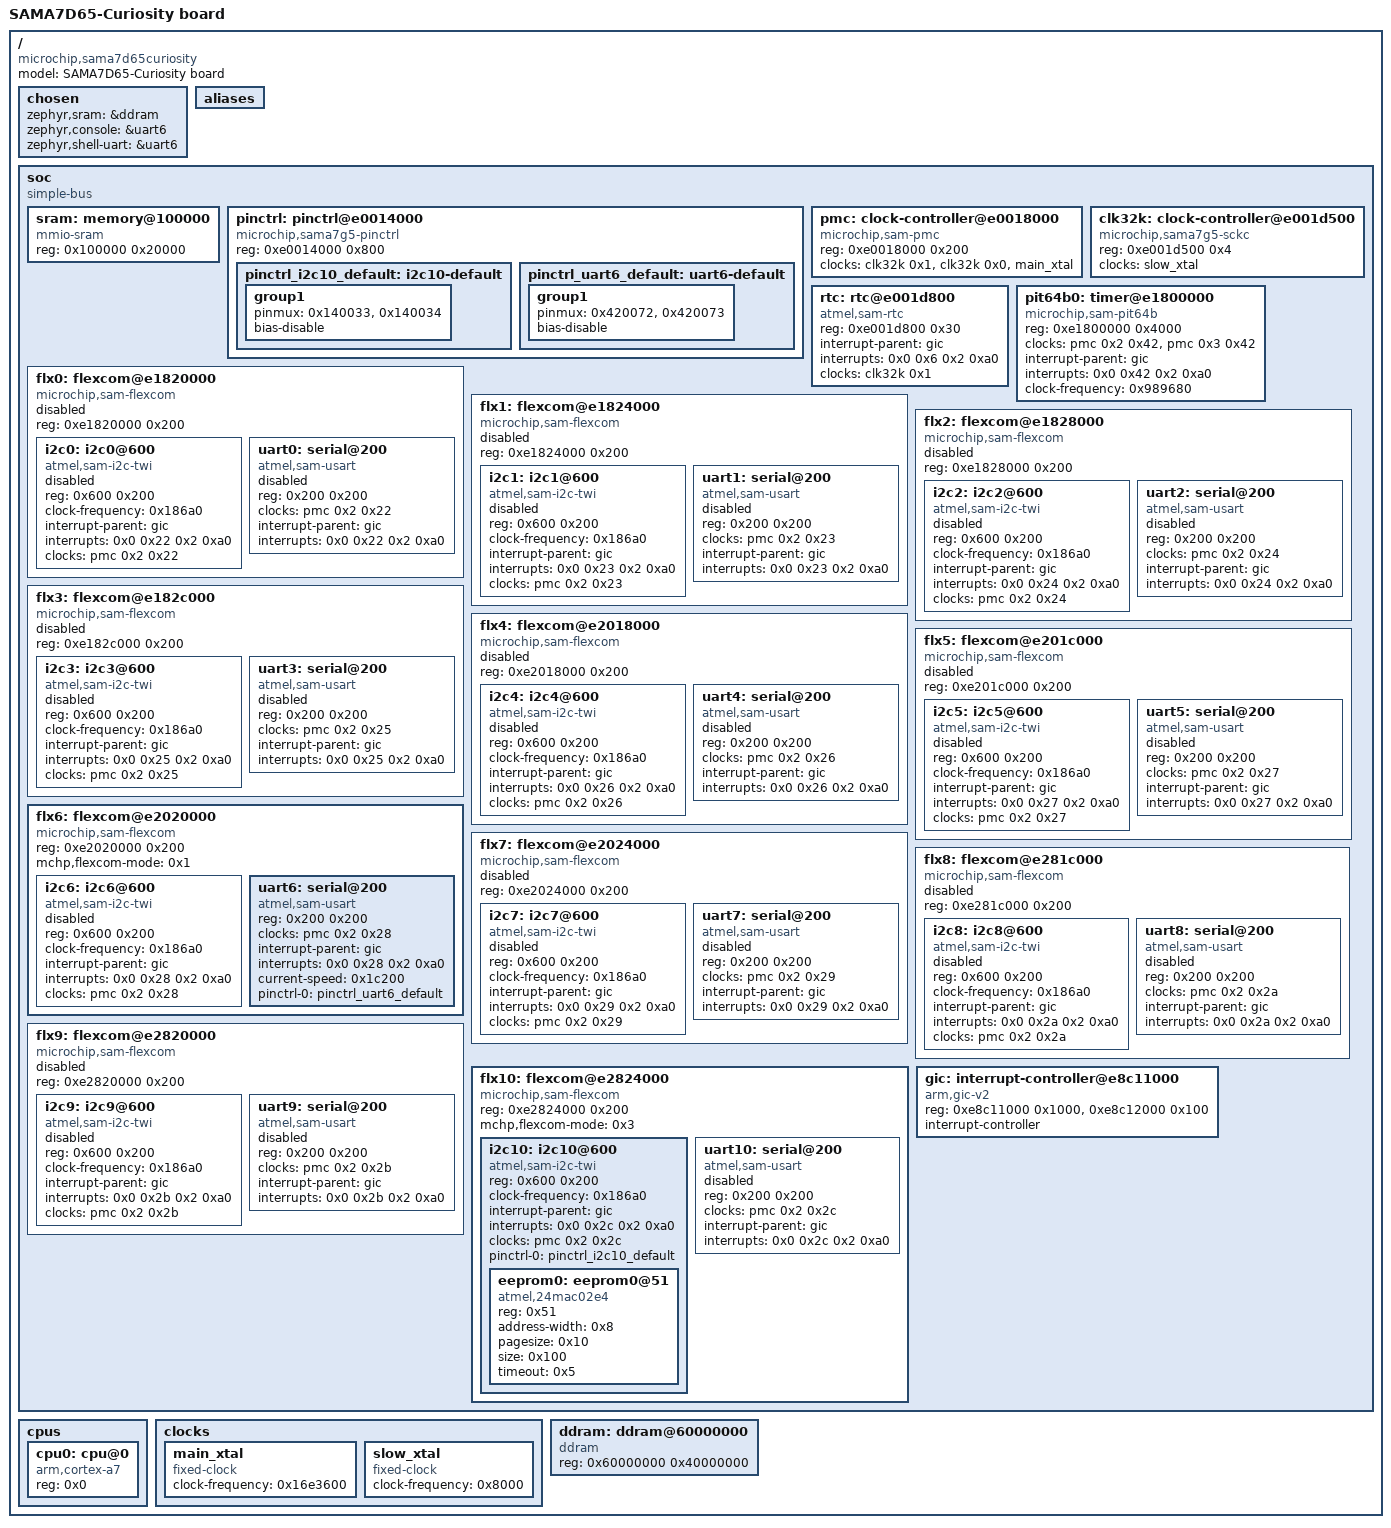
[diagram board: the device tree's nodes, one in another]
/dts-v1/;

/* node '/' defined in zephyr/dts/common/skeleton.dtsi:9 */
/ {
	#address-cells = < 0x1 >;                   /* in zephyr/dts/common/skeleton.dtsi:10 */
	#size-cells = < 0x1 >;                      /* in zephyr/dts/common/skeleton.dtsi:11 */
	model = "SAMA7D65-Curiosity board";         /* in zephyr/boards/microchip/sam/sama7d65_curiosity/sama7d65_curiosity.dts:15 */
	compatible = "microchip,sama7d65curiosity",
	             "microchip,sama7d6",
	             "microchip,sama7";             /* in zephyr/boards/microchip/sam/sama7d65_curiosity/sama7d65_curiosity.dts:16 */

	/* node '/chosen' defined in zephyr/dts/common/skeleton.dtsi:13 */
	chosen {
		zephyr,sram = &ddram;       /* in zephyr/boards/microchip/sam/sama7d65_curiosity/sama7d65_curiosity.dts:19 */
		zephyr,console = &uart6;    /* in zephyr/boards/microchip/sam/sama7d65_curiosity/sama7d65_curiosity.dts:20 */
		zephyr,shell-uart = &uart6; /* in zephyr/boards/microchip/sam/sama7d65_curiosity/sama7d65_curiosity.dts:21 */
	};

	/* node '/aliases' defined in zephyr/dts/common/skeleton.dtsi:15 */
	aliases {
	};

	/* node '/soc' defined in zephyr/dts/arm/armv7-a.dtsi:10 */
	soc {
		#address-cells = < 0x1 >;  /* in zephyr/dts/arm/armv7-a.dtsi:11 */
		#size-cells = < 0x1 >;     /* in zephyr/dts/arm/armv7-a.dtsi:12 */
		compatible = "simple-bus"; /* in zephyr/dts/arm/armv7-a.dtsi:13 */
		ranges;                    /* in zephyr/dts/arm/armv7-a.dtsi:14 */

		/* node '/soc/memory@100000' defined in zephyr/dts/arm/microchip/sam/sama7d6.dtsi:42 */
		sram: memory@100000 {
			compatible = "mmio-sram";   /* in zephyr/dts/arm/microchip/sam/sama7d6.dtsi:43 */
			reg = < 0x100000 0x20000 >; /* in zephyr/dts/arm/microchip/sam/sama7d6.dtsi:44 */
		};

		/* node '/soc/pinctrl@e0014000' defined in zephyr/dts/arm/microchip/sam/sama7d6.dtsi:47 */
		pinctrl: pinctrl@e0014000 {
			compatible = "microchip,sama7g5-pinctrl"; /* in zephyr/dts/arm/microchip/sam/sama7d6.dtsi:48 */
			reg = < 0xe0014000 0x800 >;               /* in zephyr/dts/arm/microchip/sam/sama7d6.dtsi:49 */

			/* node '/soc/pinctrl@e0014000/i2c10-default' defined in zephyr/boards/microchip/sam/sama7d65_curiosity/sama7d65_curiosity.dts:74 */
			pinctrl_i2c10_default: i2c10-default {
				phandle = < 0x7 >; /* in zephyr/boards/microchip/sam/sama7d65_curiosity/sama7d65_curiosity.dts:57 */

				/* node '/soc/pinctrl@e0014000/i2c10-default/group1' defined in zephyr/boards/microchip/sam/sama7d65_curiosity/sama7d65_curiosity.dts:75 */
				group1 {
					pinmux = < 0x140033 >,
					         < 0x140034 >; /* in zephyr/boards/microchip/sam/sama7d65_curiosity/sama7d65_curiosity.dts:76 */
					bias-disable;          /* in zephyr/boards/microchip/sam/sama7d65_curiosity/sama7d65_curiosity.dts:78 */
				};
			};

			/* node '/soc/pinctrl@e0014000/uart6-default' defined in zephyr/boards/microchip/sam/sama7d65_curiosity/sama7d65_curiosity.dts:82 */
			pinctrl_uart6_default: uart6-default {
				phandle = < 0x6 >; /* in zephyr/boards/microchip/sam/sama7d65_curiosity/sama7d65_curiosity.dts:46 */

				/* node '/soc/pinctrl@e0014000/uart6-default/group1' defined in zephyr/boards/microchip/sam/sama7d65_curiosity/sama7d65_curiosity.dts:83 */
				group1 {
					pinmux = < 0x420072 >,
					         < 0x420073 >; /* in zephyr/boards/microchip/sam/sama7d65_curiosity/sama7d65_curiosity.dts:84 */
					bias-disable;          /* in zephyr/boards/microchip/sam/sama7d65_curiosity/sama7d65_curiosity.dts:86 */
				};
			};
		};

		/* node '/soc/clock-controller@e0018000' defined in zephyr/dts/arm/microchip/sam/sama7d6.dtsi:52 */
		pmc: clock-controller@e0018000 {
			compatible = "microchip,sam-pmc"; /* in zephyr/dts/arm/microchip/sam/sama7d6.dtsi:53 */
			reg = < 0xe0018000 0x200 >;       /* in zephyr/dts/arm/microchip/sam/sama7d6.dtsi:54 */
			#clock-cells = < 0x2 >;           /* in zephyr/dts/arm/microchip/sam/sama7d6.dtsi:55 */
			clocks = < &clk32k 0x1 >,
			         < &clk32k 0x0 >,
			         < &main_xtal >;          /* in zephyr/dts/arm/microchip/sam/sama7d6.dtsi:56 */
			clock-names = "td_slck",
			              "md_slck",
			              "main_xtal";        /* in zephyr/dts/arm/microchip/sam/sama7d6.dtsi:57 */
			phandle = < 0x5 >;                /* in zephyr/dts/arm/microchip/sam/sama7d6.dtsi:78 */
		};

		/* node '/soc/clock-controller@e001d500' defined in zephyr/dts/arm/microchip/sam/sama7d6.dtsi:60 */
		clk32k: clock-controller@e001d500 {
			compatible = "microchip,sama7g5-sckc",
			             "microchip,sam9x60-sckc"; /* in zephyr/dts/arm/microchip/sam/sama7d6.dtsi:61 */
			reg = < 0xe001d500 0x4 >;              /* in zephyr/dts/arm/microchip/sam/sama7d6.dtsi:62 */
			clocks = < &slow_xtal >;               /* in zephyr/dts/arm/microchip/sam/sama7d6.dtsi:63 */
			#clock-cells = < 0x1 >;                /* in zephyr/dts/arm/microchip/sam/sama7d6.dtsi:64 */
			phandle = < 0x1 >;                     /* in zephyr/dts/arm/microchip/sam/sama7d6.dtsi:56 */
		};

		/* node '/soc/rtc@e001d800' defined in zephyr/dts/arm/microchip/sam/sama7d6.dtsi:67 */
		rtc: rtc@e001d800 {
			compatible = "atmel,sam-rtc";      /* in zephyr/dts/arm/microchip/sam/sama7d6.dtsi:68 */
			reg = < 0xe001d800 0x30 >;         /* in zephyr/dts/arm/microchip/sam/sama7d6.dtsi:69 */
			interrupt-parent = < &gic >;       /* in zephyr/dts/arm/microchip/sam/sama7d6.dtsi:70 */
			interrupts = < 0x0 0x6 0x2 0xa0 >; /* in zephyr/dts/arm/microchip/sam/sama7d6.dtsi:71 */
			clocks = < &clk32k 0x1 >;          /* in zephyr/dts/arm/microchip/sam/sama7d6.dtsi:72 */
		};

		/* node '/soc/timer@e1800000' defined in zephyr/dts/arm/microchip/sam/sama7d6.dtsi:75 */
		pit64b0: timer@e1800000 {
			compatible = "microchip,sam-pit64b",
			             "microchip,sam9x60-pit64b"; /* in zephyr/dts/arm/microchip/sam/sama7d6.dtsi:76 */
			reg = < 0xe1800000 0x4000 >;             /* in zephyr/dts/arm/microchip/sam/sama7d6.dtsi:77 */
			clocks = < &pmc 0x2 0x42 >,
			         < &pmc 0x3 0x42 >;              /* in zephyr/dts/arm/microchip/sam/sama7d6.dtsi:78 */
			clock-names = "pclk",
			              "gclk";                    /* in zephyr/dts/arm/microchip/sam/sama7d6.dtsi:79 */
			interrupt-parent = < &gic >;             /* in zephyr/dts/arm/microchip/sam/sama7d6.dtsi:80 */
			interrupts = < 0x0 0x42 0x2 0xa0 >;      /* in zephyr/dts/arm/microchip/sam/sama7d6.dtsi:81 */
			clock-frequency = < 0x989680 >;          /* in zephyr/boards/microchip/sam/sama7d65_curiosity/sama7d65_curiosity.dts:92 */
		};

		/* node '/soc/flexcom@e1820000' defined in zephyr/dts/arm/microchip/sam/sama7d6.dtsi:84 */
		flx0: flexcom@e1820000 {
			compatible = "microchip,sam-flexcom"; /* in zephyr/dts/arm/microchip/sam/sama7d6.dtsi:85 */
			reg = < 0xe1820000 0x200 >;           /* in zephyr/dts/arm/microchip/sam/sama7d6.dtsi:86 */
			#address-cells = < 0x1 >;             /* in zephyr/dts/arm/microchip/sam/sama7d6.dtsi:87 */
			#size-cells = < 0x1 >;                /* in zephyr/dts/arm/microchip/sam/sama7d6.dtsi:88 */
			ranges = < 0x0 0xe1820000 0x800 >;    /* in zephyr/dts/arm/microchip/sam/sama7d6.dtsi:89 */
			status = "disabled";                  /* in zephyr/dts/arm/microchip/sam/sama7d6.dtsi:90 */

			/* node '/soc/flexcom@e1820000/i2c0@600' defined in zephyr/dts/arm/microchip/sam/sama7d6.dtsi:92 */
			i2c0: i2c0@600 {
				compatible = "atmel,sam-i2c-twi";   /* in zephyr/dts/arm/microchip/sam/sama7d6.dtsi:93 */
				reg = < 0x600 0x200 >;              /* in zephyr/dts/arm/microchip/sam/sama7d6.dtsi:94 */
				clock-frequency = < 0x186a0 >;      /* in zephyr/dts/arm/microchip/sam/sama7d6.dtsi:95 */
				interrupt-parent = < &gic >;        /* in zephyr/dts/arm/microchip/sam/sama7d6.dtsi:96 */
				interrupts = < 0x0 0x22 0x2 0xa0 >; /* in zephyr/dts/arm/microchip/sam/sama7d6.dtsi:97 */
				#address-cells = < 0x1 >;           /* in zephyr/dts/arm/microchip/sam/sama7d6.dtsi:98 */
				#size-cells = < 0x0 >;              /* in zephyr/dts/arm/microchip/sam/sama7d6.dtsi:99 */
				clocks = < &pmc 0x2 0x22 >;         /* in zephyr/dts/arm/microchip/sam/sama7d6.dtsi:100 */
				status = "disabled";                /* in zephyr/dts/arm/microchip/sam/sama7d6.dtsi:101 */
			};

			/* node '/soc/flexcom@e1820000/serial@200' defined in zephyr/dts/arm/microchip/sam/sama7d6.dtsi:104 */
			uart0: serial@200 {
				compatible = "atmel,sam-usart";     /* in zephyr/dts/arm/microchip/sam/sama7d6.dtsi:105 */
				reg = < 0x200 0x200 >;              /* in zephyr/dts/arm/microchip/sam/sama7d6.dtsi:106 */
				clocks = < &pmc 0x2 0x22 >;         /* in zephyr/dts/arm/microchip/sam/sama7d6.dtsi:107 */
				interrupt-parent = < &gic >;        /* in zephyr/dts/arm/microchip/sam/sama7d6.dtsi:108 */
				interrupts = < 0x0 0x22 0x2 0xa0 >; /* in zephyr/dts/arm/microchip/sam/sama7d6.dtsi:109 */
				status = "disabled";                /* in zephyr/dts/arm/microchip/sam/sama7d6.dtsi:110 */
			};
		};

		/* node '/soc/flexcom@e1824000' defined in zephyr/dts/arm/microchip/sam/sama7d6.dtsi:114 */
		flx1: flexcom@e1824000 {
			compatible = "microchip,sam-flexcom"; /* in zephyr/dts/arm/microchip/sam/sama7d6.dtsi:115 */
			reg = < 0xe1824000 0x200 >;           /* in zephyr/dts/arm/microchip/sam/sama7d6.dtsi:116 */
			#address-cells = < 0x1 >;             /* in zephyr/dts/arm/microchip/sam/sama7d6.dtsi:117 */
			#size-cells = < 0x1 >;                /* in zephyr/dts/arm/microchip/sam/sama7d6.dtsi:118 */
			ranges = < 0x0 0xe1824000 0x800 >;    /* in zephyr/dts/arm/microchip/sam/sama7d6.dtsi:119 */
			status = "disabled";                  /* in zephyr/dts/arm/microchip/sam/sama7d6.dtsi:120 */

			/* node '/soc/flexcom@e1824000/i2c1@600' defined in zephyr/dts/arm/microchip/sam/sama7d6.dtsi:122 */
			i2c1: i2c1@600 {
				compatible = "atmel,sam-i2c-twi";   /* in zephyr/dts/arm/microchip/sam/sama7d6.dtsi:123 */
				reg = < 0x600 0x200 >;              /* in zephyr/dts/arm/microchip/sam/sama7d6.dtsi:124 */
				clock-frequency = < 0x186a0 >;      /* in zephyr/dts/arm/microchip/sam/sama7d6.dtsi:125 */
				interrupt-parent = < &gic >;        /* in zephyr/dts/arm/microchip/sam/sama7d6.dtsi:126 */
				interrupts = < 0x0 0x23 0x2 0xa0 >; /* in zephyr/dts/arm/microchip/sam/sama7d6.dtsi:127 */
				#address-cells = < 0x1 >;           /* in zephyr/dts/arm/microchip/sam/sama7d6.dtsi:128 */
				#size-cells = < 0x0 >;              /* in zephyr/dts/arm/microchip/sam/sama7d6.dtsi:129 */
				clocks = < &pmc 0x2 0x23 >;         /* in zephyr/dts/arm/microchip/sam/sama7d6.dtsi:130 */
				status = "disabled";                /* in zephyr/dts/arm/microchip/sam/sama7d6.dtsi:131 */
			};

			/* node '/soc/flexcom@e1824000/serial@200' defined in zephyr/dts/arm/microchip/sam/sama7d6.dtsi:134 */
			uart1: serial@200 {
				compatible = "atmel,sam-usart";     /* in zephyr/dts/arm/microchip/sam/sama7d6.dtsi:135 */
				reg = < 0x200 0x200 >;              /* in zephyr/dts/arm/microchip/sam/sama7d6.dtsi:136 */
				clocks = < &pmc 0x2 0x23 >;         /* in zephyr/dts/arm/microchip/sam/sama7d6.dtsi:137 */
				interrupt-parent = < &gic >;        /* in zephyr/dts/arm/microchip/sam/sama7d6.dtsi:138 */
				interrupts = < 0x0 0x23 0x2 0xa0 >; /* in zephyr/dts/arm/microchip/sam/sama7d6.dtsi:139 */
				status = "disabled";                /* in zephyr/dts/arm/microchip/sam/sama7d6.dtsi:140 */
			};
		};

		/* node '/soc/flexcom@e1828000' defined in zephyr/dts/arm/microchip/sam/sama7d6.dtsi:144 */
		flx2: flexcom@e1828000 {
			compatible = "microchip,sam-flexcom"; /* in zephyr/dts/arm/microchip/sam/sama7d6.dtsi:145 */
			reg = < 0xe1828000 0x200 >;           /* in zephyr/dts/arm/microchip/sam/sama7d6.dtsi:146 */
			#address-cells = < 0x1 >;             /* in zephyr/dts/arm/microchip/sam/sama7d6.dtsi:147 */
			#size-cells = < 0x1 >;                /* in zephyr/dts/arm/microchip/sam/sama7d6.dtsi:148 */
			ranges = < 0x0 0xe1828000 0x800 >;    /* in zephyr/dts/arm/microchip/sam/sama7d6.dtsi:149 */
			status = "disabled";                  /* in zephyr/dts/arm/microchip/sam/sama7d6.dtsi:150 */

			/* node '/soc/flexcom@e1828000/i2c2@600' defined in zephyr/dts/arm/microchip/sam/sama7d6.dtsi:152 */
			i2c2: i2c2@600 {
				compatible = "atmel,sam-i2c-twi";   /* in zephyr/dts/arm/microchip/sam/sama7d6.dtsi:153 */
				reg = < 0x600 0x200 >;              /* in zephyr/dts/arm/microchip/sam/sama7d6.dtsi:154 */
				clock-frequency = < 0x186a0 >;      /* in zephyr/dts/arm/microchip/sam/sama7d6.dtsi:155 */
				interrupt-parent = < &gic >;        /* in zephyr/dts/arm/microchip/sam/sama7d6.dtsi:156 */
				interrupts = < 0x0 0x24 0x2 0xa0 >; /* in zephyr/dts/arm/microchip/sam/sama7d6.dtsi:157 */
				#address-cells = < 0x1 >;           /* in zephyr/dts/arm/microchip/sam/sama7d6.dtsi:158 */
				#size-cells = < 0x0 >;              /* in zephyr/dts/arm/microchip/sam/sama7d6.dtsi:159 */
				clocks = < &pmc 0x2 0x24 >;         /* in zephyr/dts/arm/microchip/sam/sama7d6.dtsi:160 */
				status = "disabled";                /* in zephyr/dts/arm/microchip/sam/sama7d6.dtsi:161 */
			};

			/* node '/soc/flexcom@e1828000/serial@200' defined in zephyr/dts/arm/microchip/sam/sama7d6.dtsi:164 */
			uart2: serial@200 {
				compatible = "atmel,sam-usart";     /* in zephyr/dts/arm/microchip/sam/sama7d6.dtsi:165 */
				reg = < 0x200 0x200 >;              /* in zephyr/dts/arm/microchip/sam/sama7d6.dtsi:166 */
				clocks = < &pmc 0x2 0x24 >;         /* in zephyr/dts/arm/microchip/sam/sama7d6.dtsi:167 */
				interrupt-parent = < &gic >;        /* in zephyr/dts/arm/microchip/sam/sama7d6.dtsi:168 */
				interrupts = < 0x0 0x24 0x2 0xa0 >; /* in zephyr/dts/arm/microchip/sam/sama7d6.dtsi:169 */
				status = "disabled";                /* in zephyr/dts/arm/microchip/sam/sama7d6.dtsi:170 */
			};
		};

		/* node '/soc/flexcom@e182c000' defined in zephyr/dts/arm/microchip/sam/sama7d6.dtsi:174 */
		flx3: flexcom@e182c000 {
			compatible = "microchip,sam-flexcom"; /* in zephyr/dts/arm/microchip/sam/sama7d6.dtsi:175 */
			reg = < 0xe182c000 0x200 >;           /* in zephyr/dts/arm/microchip/sam/sama7d6.dtsi:176 */
			#address-cells = < 0x1 >;             /* in zephyr/dts/arm/microchip/sam/sama7d6.dtsi:177 */
			#size-cells = < 0x1 >;                /* in zephyr/dts/arm/microchip/sam/sama7d6.dtsi:178 */
			ranges = < 0x0 0xe182c000 0x800 >;    /* in zephyr/dts/arm/microchip/sam/sama7d6.dtsi:179 */
			status = "disabled";                  /* in zephyr/dts/arm/microchip/sam/sama7d6.dtsi:180 */

			/* node '/soc/flexcom@e182c000/i2c3@600' defined in zephyr/dts/arm/microchip/sam/sama7d6.dtsi:182 */
			i2c3: i2c3@600 {
				compatible = "atmel,sam-i2c-twi";   /* in zephyr/dts/arm/microchip/sam/sama7d6.dtsi:183 */
				reg = < 0x600 0x200 >;              /* in zephyr/dts/arm/microchip/sam/sama7d6.dtsi:184 */
				clock-frequency = < 0x186a0 >;      /* in zephyr/dts/arm/microchip/sam/sama7d6.dtsi:185 */
				interrupt-parent = < &gic >;        /* in zephyr/dts/arm/microchip/sam/sama7d6.dtsi:186 */
				interrupts = < 0x0 0x25 0x2 0xa0 >; /* in zephyr/dts/arm/microchip/sam/sama7d6.dtsi:187 */
				#address-cells = < 0x1 >;           /* in zephyr/dts/arm/microchip/sam/sama7d6.dtsi:188 */
				#size-cells = < 0x0 >;              /* in zephyr/dts/arm/microchip/sam/sama7d6.dtsi:189 */
				clocks = < &pmc 0x2 0x25 >;         /* in zephyr/dts/arm/microchip/sam/sama7d6.dtsi:190 */
				status = "disabled";                /* in zephyr/dts/arm/microchip/sam/sama7d6.dtsi:191 */
			};

			/* node '/soc/flexcom@e182c000/serial@200' defined in zephyr/dts/arm/microchip/sam/sama7d6.dtsi:194 */
			uart3: serial@200 {
				compatible = "atmel,sam-usart";     /* in zephyr/dts/arm/microchip/sam/sama7d6.dtsi:195 */
				reg = < 0x200 0x200 >;              /* in zephyr/dts/arm/microchip/sam/sama7d6.dtsi:196 */
				clocks = < &pmc 0x2 0x25 >;         /* in zephyr/dts/arm/microchip/sam/sama7d6.dtsi:197 */
				interrupt-parent = < &gic >;        /* in zephyr/dts/arm/microchip/sam/sama7d6.dtsi:198 */
				interrupts = < 0x0 0x25 0x2 0xa0 >; /* in zephyr/dts/arm/microchip/sam/sama7d6.dtsi:199 */
				status = "disabled";                /* in zephyr/dts/arm/microchip/sam/sama7d6.dtsi:200 */
			};
		};

		/* node '/soc/flexcom@e2018000' defined in zephyr/dts/arm/microchip/sam/sama7d6.dtsi:204 */
		flx4: flexcom@e2018000 {
			compatible = "microchip,sam-flexcom"; /* in zephyr/dts/arm/microchip/sam/sama7d6.dtsi:205 */
			reg = < 0xe2018000 0x200 >;           /* in zephyr/dts/arm/microchip/sam/sama7d6.dtsi:206 */
			#address-cells = < 0x1 >;             /* in zephyr/dts/arm/microchip/sam/sama7d6.dtsi:207 */
			#size-cells = < 0x1 >;                /* in zephyr/dts/arm/microchip/sam/sama7d6.dtsi:208 */
			ranges = < 0x0 0xe2018000 0x800 >;    /* in zephyr/dts/arm/microchip/sam/sama7d6.dtsi:209 */
			status = "disabled";                  /* in zephyr/dts/arm/microchip/sam/sama7d6.dtsi:210 */

			/* node '/soc/flexcom@e2018000/i2c4@600' defined in zephyr/dts/arm/microchip/sam/sama7d6.dtsi:212 */
			i2c4: i2c4@600 {
				compatible = "atmel,sam-i2c-twi";   /* in zephyr/dts/arm/microchip/sam/sama7d6.dtsi:213 */
				reg = < 0x600 0x200 >;              /* in zephyr/dts/arm/microchip/sam/sama7d6.dtsi:214 */
				clock-frequency = < 0x186a0 >;      /* in zephyr/dts/arm/microchip/sam/sama7d6.dtsi:215 */
				interrupt-parent = < &gic >;        /* in zephyr/dts/arm/microchip/sam/sama7d6.dtsi:216 */
				interrupts = < 0x0 0x26 0x2 0xa0 >; /* in zephyr/dts/arm/microchip/sam/sama7d6.dtsi:217 */
				#address-cells = < 0x1 >;           /* in zephyr/dts/arm/microchip/sam/sama7d6.dtsi:218 */
				#size-cells = < 0x0 >;              /* in zephyr/dts/arm/microchip/sam/sama7d6.dtsi:219 */
				clocks = < &pmc 0x2 0x26 >;         /* in zephyr/dts/arm/microchip/sam/sama7d6.dtsi:220 */
				status = "disabled";                /* in zephyr/dts/arm/microchip/sam/sama7d6.dtsi:221 */
			};

			/* node '/soc/flexcom@e2018000/serial@200' defined in zephyr/dts/arm/microchip/sam/sama7d6.dtsi:224 */
			uart4: serial@200 {
				compatible = "atmel,sam-usart";     /* in zephyr/dts/arm/microchip/sam/sama7d6.dtsi:225 */
				reg = < 0x200 0x200 >;              /* in zephyr/dts/arm/microchip/sam/sama7d6.dtsi:226 */
				clocks = < &pmc 0x2 0x26 >;         /* in zephyr/dts/arm/microchip/sam/sama7d6.dtsi:227 */
				interrupt-parent = < &gic >;        /* in zephyr/dts/arm/microchip/sam/sama7d6.dtsi:228 */
				interrupts = < 0x0 0x26 0x2 0xa0 >; /* in zephyr/dts/arm/microchip/sam/sama7d6.dtsi:229 */
				status = "disabled";                /* in zephyr/dts/arm/microchip/sam/sama7d6.dtsi:230 */
			};
		};

		/* node '/soc/flexcom@e201c000' defined in zephyr/dts/arm/microchip/sam/sama7d6.dtsi:234 */
		flx5: flexcom@e201c000 {
			compatible = "microchip,sam-flexcom"; /* in zephyr/dts/arm/microchip/sam/sama7d6.dtsi:235 */
			reg = < 0xe201c000 0x200 >;           /* in zephyr/dts/arm/microchip/sam/sama7d6.dtsi:236 */
			#address-cells = < 0x1 >;             /* in zephyr/dts/arm/microchip/sam/sama7d6.dtsi:237 */
			#size-cells = < 0x1 >;                /* in zephyr/dts/arm/microchip/sam/sama7d6.dtsi:238 */
			ranges = < 0x0 0xe201c000 0x800 >;    /* in zephyr/dts/arm/microchip/sam/sama7d6.dtsi:239 */
			status = "disabled";                  /* in zephyr/dts/arm/microchip/sam/sama7d6.dtsi:240 */

			/* node '/soc/flexcom@e201c000/i2c5@600' defined in zephyr/dts/arm/microchip/sam/sama7d6.dtsi:242 */
			i2c5: i2c5@600 {
				compatible = "atmel,sam-i2c-twi";   /* in zephyr/dts/arm/microchip/sam/sama7d6.dtsi:243 */
				reg = < 0x600 0x200 >;              /* in zephyr/dts/arm/microchip/sam/sama7d6.dtsi:244 */
				clock-frequency = < 0x186a0 >;      /* in zephyr/dts/arm/microchip/sam/sama7d6.dtsi:245 */
				interrupt-parent = < &gic >;        /* in zephyr/dts/arm/microchip/sam/sama7d6.dtsi:246 */
				interrupts = < 0x0 0x27 0x2 0xa0 >; /* in zephyr/dts/arm/microchip/sam/sama7d6.dtsi:247 */
				#address-cells = < 0x1 >;           /* in zephyr/dts/arm/microchip/sam/sama7d6.dtsi:248 */
				#size-cells = < 0x0 >;              /* in zephyr/dts/arm/microchip/sam/sama7d6.dtsi:249 */
				clocks = < &pmc 0x2 0x27 >;         /* in zephyr/dts/arm/microchip/sam/sama7d6.dtsi:250 */
				status = "disabled";                /* in zephyr/dts/arm/microchip/sam/sama7d6.dtsi:251 */
			};

			/* node '/soc/flexcom@e201c000/serial@200' defined in zephyr/dts/arm/microchip/sam/sama7d6.dtsi:254 */
			uart5: serial@200 {
				compatible = "atmel,sam-usart";     /* in zephyr/dts/arm/microchip/sam/sama7d6.dtsi:255 */
				reg = < 0x200 0x200 >;              /* in zephyr/dts/arm/microchip/sam/sama7d6.dtsi:256 */
				clocks = < &pmc 0x2 0x27 >;         /* in zephyr/dts/arm/microchip/sam/sama7d6.dtsi:257 */
				interrupt-parent = < &gic >;        /* in zephyr/dts/arm/microchip/sam/sama7d6.dtsi:258 */
				interrupts = < 0x0 0x27 0x2 0xa0 >; /* in zephyr/dts/arm/microchip/sam/sama7d6.dtsi:259 */
				status = "disabled";                /* in zephyr/dts/arm/microchip/sam/sama7d6.dtsi:260 */
			};
		};

		/* node '/soc/flexcom@e2020000' defined in zephyr/dts/arm/microchip/sam/sama7d6.dtsi:264 */
		flx6: flexcom@e2020000 {
			compatible = "microchip,sam-flexcom"; /* in zephyr/dts/arm/microchip/sam/sama7d6.dtsi:265 */
			reg = < 0xe2020000 0x200 >;           /* in zephyr/dts/arm/microchip/sam/sama7d6.dtsi:266 */
			#address-cells = < 0x1 >;             /* in zephyr/dts/arm/microchip/sam/sama7d6.dtsi:267 */
			#size-cells = < 0x1 >;                /* in zephyr/dts/arm/microchip/sam/sama7d6.dtsi:268 */
			ranges = < 0x0 0xe2020000 0x800 >;    /* in zephyr/dts/arm/microchip/sam/sama7d6.dtsi:269 */
			mchp,flexcom-mode = < 0x1 >;          /* in zephyr/boards/microchip/sam/sama7d65_curiosity/sama7d65_curiosity.dts:41 */
			status = "okay";                      /* in zephyr/boards/microchip/sam/sama7d65_curiosity/sama7d65_curiosity.dts:42 */

			/* node '/soc/flexcom@e2020000/i2c6@600' defined in zephyr/dts/arm/microchip/sam/sama7d6.dtsi:272 */
			i2c6: i2c6@600 {
				compatible = "atmel,sam-i2c-twi";   /* in zephyr/dts/arm/microchip/sam/sama7d6.dtsi:273 */
				reg = < 0x600 0x200 >;              /* in zephyr/dts/arm/microchip/sam/sama7d6.dtsi:274 */
				clock-frequency = < 0x186a0 >;      /* in zephyr/dts/arm/microchip/sam/sama7d6.dtsi:275 */
				interrupt-parent = < &gic >;        /* in zephyr/dts/arm/microchip/sam/sama7d6.dtsi:276 */
				interrupts = < 0x0 0x28 0x2 0xa0 >; /* in zephyr/dts/arm/microchip/sam/sama7d6.dtsi:277 */
				#address-cells = < 0x1 >;           /* in zephyr/dts/arm/microchip/sam/sama7d6.dtsi:278 */
				#size-cells = < 0x0 >;              /* in zephyr/dts/arm/microchip/sam/sama7d6.dtsi:279 */
				clocks = < &pmc 0x2 0x28 >;         /* in zephyr/dts/arm/microchip/sam/sama7d6.dtsi:280 */
				status = "disabled";                /* in zephyr/dts/arm/microchip/sam/sama7d6.dtsi:281 */
			};

			/* node '/soc/flexcom@e2020000/serial@200' defined in zephyr/dts/arm/microchip/sam/sama7d6.dtsi:284 */
			uart6: serial@200 {
				compatible = "atmel,sam-usart";         /* in zephyr/dts/arm/microchip/sam/sama7d6.dtsi:285 */
				reg = < 0x200 0x200 >;                  /* in zephyr/dts/arm/microchip/sam/sama7d6.dtsi:286 */
				clocks = < &pmc 0x2 0x28 >;             /* in zephyr/dts/arm/microchip/sam/sama7d6.dtsi:287 */
				interrupt-parent = < &gic >;            /* in zephyr/dts/arm/microchip/sam/sama7d6.dtsi:288 */
				interrupts = < 0x0 0x28 0x2 0xa0 >;     /* in zephyr/dts/arm/microchip/sam/sama7d6.dtsi:289 */
				current-speed = < 0x1c200 >;            /* in zephyr/boards/microchip/sam/sama7d65_curiosity/sama7d65_curiosity.dts:45 */
				pinctrl-0 = < &pinctrl_uart6_default >; /* in zephyr/boards/microchip/sam/sama7d65_curiosity/sama7d65_curiosity.dts:46 */
				pinctrl-names = "default";              /* in zephyr/boards/microchip/sam/sama7d65_curiosity/sama7d65_curiosity.dts:47 */
				status = "okay";                        /* in zephyr/boards/microchip/sam/sama7d65_curiosity/sama7d65_curiosity.dts:48 */
			};
		};

		/* node '/soc/flexcom@e2024000' defined in zephyr/dts/arm/microchip/sam/sama7d6.dtsi:294 */
		flx7: flexcom@e2024000 {
			compatible = "microchip,sam-flexcom"; /* in zephyr/dts/arm/microchip/sam/sama7d6.dtsi:295 */
			reg = < 0xe2024000 0x200 >;           /* in zephyr/dts/arm/microchip/sam/sama7d6.dtsi:296 */
			#address-cells = < 0x1 >;             /* in zephyr/dts/arm/microchip/sam/sama7d6.dtsi:297 */
			#size-cells = < 0x1 >;                /* in zephyr/dts/arm/microchip/sam/sama7d6.dtsi:298 */
			ranges = < 0x0 0xe2024000 0x800 >;    /* in zephyr/dts/arm/microchip/sam/sama7d6.dtsi:299 */
			status = "disabled";                  /* in zephyr/dts/arm/microchip/sam/sama7d6.dtsi:300 */

			/* node '/soc/flexcom@e2024000/i2c7@600' defined in zephyr/dts/arm/microchip/sam/sama7d6.dtsi:302 */
			i2c7: i2c7@600 {
				compatible = "atmel,sam-i2c-twi";   /* in zephyr/dts/arm/microchip/sam/sama7d6.dtsi:303 */
				reg = < 0x600 0x200 >;              /* in zephyr/dts/arm/microchip/sam/sama7d6.dtsi:304 */
				clock-frequency = < 0x186a0 >;      /* in zephyr/dts/arm/microchip/sam/sama7d6.dtsi:305 */
				interrupt-parent = < &gic >;        /* in zephyr/dts/arm/microchip/sam/sama7d6.dtsi:306 */
				interrupts = < 0x0 0x29 0x2 0xa0 >; /* in zephyr/dts/arm/microchip/sam/sama7d6.dtsi:307 */
				#address-cells = < 0x1 >;           /* in zephyr/dts/arm/microchip/sam/sama7d6.dtsi:308 */
				#size-cells = < 0x0 >;              /* in zephyr/dts/arm/microchip/sam/sama7d6.dtsi:309 */
				clocks = < &pmc 0x2 0x29 >;         /* in zephyr/dts/arm/microchip/sam/sama7d6.dtsi:310 */
				status = "disabled";                /* in zephyr/dts/arm/microchip/sam/sama7d6.dtsi:311 */
			};

			/* node '/soc/flexcom@e2024000/serial@200' defined in zephyr/dts/arm/microchip/sam/sama7d6.dtsi:314 */
			uart7: serial@200 {
				compatible = "atmel,sam-usart";     /* in zephyr/dts/arm/microchip/sam/sama7d6.dtsi:315 */
				reg = < 0x200 0x200 >;              /* in zephyr/dts/arm/microchip/sam/sama7d6.dtsi:316 */
				clocks = < &pmc 0x2 0x29 >;         /* in zephyr/dts/arm/microchip/sam/sama7d6.dtsi:317 */
				interrupt-parent = < &gic >;        /* in zephyr/dts/arm/microchip/sam/sama7d6.dtsi:318 */
				interrupts = < 0x0 0x29 0x2 0xa0 >; /* in zephyr/dts/arm/microchip/sam/sama7d6.dtsi:319 */
				status = "disabled";                /* in zephyr/dts/arm/microchip/sam/sama7d6.dtsi:320 */
			};
		};

		/* node '/soc/flexcom@e281c000' defined in zephyr/dts/arm/microchip/sam/sama7d6.dtsi:324 */
		flx8: flexcom@e281c000 {
			compatible = "microchip,sam-flexcom"; /* in zephyr/dts/arm/microchip/sam/sama7d6.dtsi:325 */
			reg = < 0xe281c000 0x200 >;           /* in zephyr/dts/arm/microchip/sam/sama7d6.dtsi:326 */
			#address-cells = < 0x1 >;             /* in zephyr/dts/arm/microchip/sam/sama7d6.dtsi:327 */
			#size-cells = < 0x1 >;                /* in zephyr/dts/arm/microchip/sam/sama7d6.dtsi:328 */
			ranges = < 0x0 0xe281c000 0x800 >;    /* in zephyr/dts/arm/microchip/sam/sama7d6.dtsi:329 */
			status = "disabled";                  /* in zephyr/dts/arm/microchip/sam/sama7d6.dtsi:330 */

			/* node '/soc/flexcom@e281c000/i2c8@600' defined in zephyr/dts/arm/microchip/sam/sama7d6.dtsi:332 */
			i2c8: i2c8@600 {
				compatible = "atmel,sam-i2c-twi";   /* in zephyr/dts/arm/microchip/sam/sama7d6.dtsi:333 */
				reg = < 0x600 0x200 >;              /* in zephyr/dts/arm/microchip/sam/sama7d6.dtsi:334 */
				clock-frequency = < 0x186a0 >;      /* in zephyr/dts/arm/microchip/sam/sama7d6.dtsi:335 */
				interrupt-parent = < &gic >;        /* in zephyr/dts/arm/microchip/sam/sama7d6.dtsi:336 */
				interrupts = < 0x0 0x2a 0x2 0xa0 >; /* in zephyr/dts/arm/microchip/sam/sama7d6.dtsi:337 */
				#address-cells = < 0x1 >;           /* in zephyr/dts/arm/microchip/sam/sama7d6.dtsi:338 */
				#size-cells = < 0x0 >;              /* in zephyr/dts/arm/microchip/sam/sama7d6.dtsi:339 */
				clocks = < &pmc 0x2 0x2a >;         /* in zephyr/dts/arm/microchip/sam/sama7d6.dtsi:340 */
				status = "disabled";                /* in zephyr/dts/arm/microchip/sam/sama7d6.dtsi:341 */
			};

			/* node '/soc/flexcom@e281c000/serial@200' defined in zephyr/dts/arm/microchip/sam/sama7d6.dtsi:344 */
			uart8: serial@200 {
				compatible = "atmel,sam-usart";     /* in zephyr/dts/arm/microchip/sam/sama7d6.dtsi:345 */
				reg = < 0x200 0x200 >;              /* in zephyr/dts/arm/microchip/sam/sama7d6.dtsi:346 */
				clocks = < &pmc 0x2 0x2a >;         /* in zephyr/dts/arm/microchip/sam/sama7d6.dtsi:347 */
				interrupt-parent = < &gic >;        /* in zephyr/dts/arm/microchip/sam/sama7d6.dtsi:348 */
				interrupts = < 0x0 0x2a 0x2 0xa0 >; /* in zephyr/dts/arm/microchip/sam/sama7d6.dtsi:349 */
				status = "disabled";                /* in zephyr/dts/arm/microchip/sam/sama7d6.dtsi:350 */
			};
		};

		/* node '/soc/flexcom@e2820000' defined in zephyr/dts/arm/microchip/sam/sama7d6.dtsi:354 */
		flx9: flexcom@e2820000 {
			compatible = "microchip,sam-flexcom"; /* in zephyr/dts/arm/microchip/sam/sama7d6.dtsi:355 */
			reg = < 0xe2820000 0x200 >;           /* in zephyr/dts/arm/microchip/sam/sama7d6.dtsi:356 */
			#address-cells = < 0x1 >;             /* in zephyr/dts/arm/microchip/sam/sama7d6.dtsi:357 */
			#size-cells = < 0x1 >;                /* in zephyr/dts/arm/microchip/sam/sama7d6.dtsi:358 */
			ranges = < 0x0 0xe2820000 0x800 >;    /* in zephyr/dts/arm/microchip/sam/sama7d6.dtsi:359 */
			status = "disabled";                  /* in zephyr/dts/arm/microchip/sam/sama7d6.dtsi:360 */

			/* node '/soc/flexcom@e2820000/i2c9@600' defined in zephyr/dts/arm/microchip/sam/sama7d6.dtsi:362 */
			i2c9: i2c9@600 {
				compatible = "atmel,sam-i2c-twi";   /* in zephyr/dts/arm/microchip/sam/sama7d6.dtsi:363 */
				reg = < 0x600 0x200 >;              /* in zephyr/dts/arm/microchip/sam/sama7d6.dtsi:364 */
				clock-frequency = < 0x186a0 >;      /* in zephyr/dts/arm/microchip/sam/sama7d6.dtsi:365 */
				interrupt-parent = < &gic >;        /* in zephyr/dts/arm/microchip/sam/sama7d6.dtsi:366 */
				interrupts = < 0x0 0x2b 0x2 0xa0 >; /* in zephyr/dts/arm/microchip/sam/sama7d6.dtsi:367 */
				#address-cells = < 0x1 >;           /* in zephyr/dts/arm/microchip/sam/sama7d6.dtsi:368 */
				#size-cells = < 0x0 >;              /* in zephyr/dts/arm/microchip/sam/sama7d6.dtsi:369 */
				clocks = < &pmc 0x2 0x2b >;         /* in zephyr/dts/arm/microchip/sam/sama7d6.dtsi:370 */
				status = "disabled";                /* in zephyr/dts/arm/microchip/sam/sama7d6.dtsi:371 */
			};

			/* node '/soc/flexcom@e2820000/serial@200' defined in zephyr/dts/arm/microchip/sam/sama7d6.dtsi:374 */
			uart9: serial@200 {
				compatible = "atmel,sam-usart";     /* in zephyr/dts/arm/microchip/sam/sama7d6.dtsi:375 */
				reg = < 0x200 0x200 >;              /* in zephyr/dts/arm/microchip/sam/sama7d6.dtsi:376 */
				clocks = < &pmc 0x2 0x2b >;         /* in zephyr/dts/arm/microchip/sam/sama7d6.dtsi:377 */
				interrupt-parent = < &gic >;        /* in zephyr/dts/arm/microchip/sam/sama7d6.dtsi:378 */
				interrupts = < 0x0 0x2b 0x2 0xa0 >; /* in zephyr/dts/arm/microchip/sam/sama7d6.dtsi:379 */
				status = "disabled";                /* in zephyr/dts/arm/microchip/sam/sama7d6.dtsi:380 */
			};
		};

		/* node '/soc/flexcom@e2824000' defined in zephyr/dts/arm/microchip/sam/sama7d6.dtsi:384 */
		flx10: flexcom@e2824000 {
			compatible = "microchip,sam-flexcom"; /* in zephyr/dts/arm/microchip/sam/sama7d6.dtsi:385 */
			reg = < 0xe2824000 0x200 >;           /* in zephyr/dts/arm/microchip/sam/sama7d6.dtsi:386 */
			#address-cells = < 0x1 >;             /* in zephyr/dts/arm/microchip/sam/sama7d6.dtsi:387 */
			#size-cells = < 0x1 >;                /* in zephyr/dts/arm/microchip/sam/sama7d6.dtsi:388 */
			ranges = < 0x0 0xe2824000 0x800 >;    /* in zephyr/dts/arm/microchip/sam/sama7d6.dtsi:389 */
			mchp,flexcom-mode = < 0x3 >;          /* in zephyr/boards/microchip/sam/sama7d65_curiosity/sama7d65_curiosity.dts:53 */
			status = "okay";                      /* in zephyr/boards/microchip/sam/sama7d65_curiosity/sama7d65_curiosity.dts:54 */

			/* node '/soc/flexcom@e2824000/i2c10@600' defined in zephyr/dts/arm/microchip/sam/sama7d6.dtsi:392 */
			i2c10: i2c10@600 {
				compatible = "atmel,sam-i2c-twi";       /* in zephyr/dts/arm/microchip/sam/sama7d6.dtsi:393 */
				reg = < 0x600 0x200 >;                  /* in zephyr/dts/arm/microchip/sam/sama7d6.dtsi:394 */
				clock-frequency = < 0x186a0 >;          /* in zephyr/dts/arm/microchip/sam/sama7d6.dtsi:395 */
				interrupt-parent = < &gic >;            /* in zephyr/dts/arm/microchip/sam/sama7d6.dtsi:396 */
				interrupts = < 0x0 0x2c 0x2 0xa0 >;     /* in zephyr/dts/arm/microchip/sam/sama7d6.dtsi:397 */
				#address-cells = < 0x1 >;               /* in zephyr/dts/arm/microchip/sam/sama7d6.dtsi:398 */
				#size-cells = < 0x0 >;                  /* in zephyr/dts/arm/microchip/sam/sama7d6.dtsi:399 */
				clocks = < &pmc 0x2 0x2c >;             /* in zephyr/dts/arm/microchip/sam/sama7d6.dtsi:400 */
				pinctrl-0 = < &pinctrl_i2c10_default >; /* in zephyr/boards/microchip/sam/sama7d65_curiosity/sama7d65_curiosity.dts:57 */
				pinctrl-names = "default";              /* in zephyr/boards/microchip/sam/sama7d65_curiosity/sama7d65_curiosity.dts:58 */
				status = "okay";                        /* in zephyr/boards/microchip/sam/sama7d65_curiosity/sama7d65_curiosity.dts:59 */

				/* node '/soc/flexcom@e2824000/i2c10@600/eeprom0@51' defined in zephyr/boards/microchip/sam/sama7d65_curiosity/sama7d65_curiosity.dts:61 */
				eeprom0: eeprom0@51 {
					compatible = "atmel,24mac02e4",
					             "atmel,at24";      /* in zephyr/boards/microchip/sam/sama7d65_curiosity/sama7d65_curiosity.dts:62 */
					reg = < 0x51 >;                 /* in zephyr/boards/microchip/sam/sama7d65_curiosity/sama7d65_curiosity.dts:63 */
					address-width = < 0x8 >;        /* in zephyr/boards/microchip/sam/sama7d65_curiosity/sama7d65_curiosity.dts:64 */
					pagesize = < 0x10 >;            /* in zephyr/boards/microchip/sam/sama7d65_curiosity/sama7d65_curiosity.dts:65 */
					size = < 0x100 >;               /* in zephyr/boards/microchip/sam/sama7d65_curiosity/sama7d65_curiosity.dts:66 */
					timeout = < 0x5 >;              /* in zephyr/boards/microchip/sam/sama7d65_curiosity/sama7d65_curiosity.dts:67 */
					status = "okay";                /* in zephyr/boards/microchip/sam/sama7d65_curiosity/sama7d65_curiosity.dts:68 */
				};
			};

			/* node '/soc/flexcom@e2824000/serial@200' defined in zephyr/dts/arm/microchip/sam/sama7d6.dtsi:404 */
			uart10: serial@200 {
				compatible = "atmel,sam-usart";     /* in zephyr/dts/arm/microchip/sam/sama7d6.dtsi:405 */
				reg = < 0x200 0x200 >;              /* in zephyr/dts/arm/microchip/sam/sama7d6.dtsi:406 */
				clocks = < &pmc 0x2 0x2c >;         /* in zephyr/dts/arm/microchip/sam/sama7d6.dtsi:407 */
				interrupt-parent = < &gic >;        /* in zephyr/dts/arm/microchip/sam/sama7d6.dtsi:408 */
				interrupts = < 0x0 0x2c 0x2 0xa0 >; /* in zephyr/dts/arm/microchip/sam/sama7d6.dtsi:409 */
				status = "disabled";                /* in zephyr/dts/arm/microchip/sam/sama7d6.dtsi:410 */
			};
		};

		/* node '/soc/interrupt-controller@e8c11000' defined in zephyr/dts/arm/microchip/sam/sama7d6.dtsi:414 */
		gic: interrupt-controller@e8c11000 {
			compatible = "arm,gic-v2",
			             "arm,gic";      /* in zephyr/dts/arm/microchip/sam/sama7d6.dtsi:415 */
			reg = < 0xe8c11000 0x1000 >,
			      < 0xe8c12000 0x100 >;  /* in zephyr/dts/arm/microchip/sam/sama7d6.dtsi:416 */
			interrupt-controller;        /* in zephyr/dts/arm/microchip/sam/sama7d6.dtsi:417 */
			#interrupt-cells = < 0x4 >;  /* in zephyr/dts/arm/microchip/sam/sama7d6.dtsi:418 */
			phandle = < 0x4 >;           /* in zephyr/dts/arm/microchip/sam/sama7d6.dtsi:70 */
		};
	};

	/* node '/cpus' defined in zephyr/dts/arm/microchip/sam/sama7d6.dtsi:18 */
	cpus {
		#address-cells = < 0x1 >; /* in zephyr/dts/arm/microchip/sam/sama7d6.dtsi:19 */
		#size-cells = < 0x0 >;    /* in zephyr/dts/arm/microchip/sam/sama7d6.dtsi:20 */

		/* node '/cpus/cpu@0' defined in zephyr/dts/arm/microchip/sam/sama7d6.dtsi:22 */
		cpu0: cpu@0 {
			device_type = "cpu";          /* in zephyr/dts/arm/microchip/sam/sama7d6.dtsi:23 */
			compatible = "arm,cortex-a7"; /* in zephyr/dts/arm/microchip/sam/sama7d6.dtsi:24 */
			reg = < 0x0 >;                /* in zephyr/dts/arm/microchip/sam/sama7d6.dtsi:25 */
		};
	};

	/* node '/clocks' defined in zephyr/dts/arm/microchip/sam/sama7d6.dtsi:29 */
	clocks {

		/* node '/clocks/main_xtal' defined in zephyr/dts/arm/microchip/sam/sama7d6.dtsi:30 */
		main_xtal: main_xtal {
			compatible = "fixed-clock";      /* in zephyr/dts/arm/microchip/sam/sama7d6.dtsi:31 */
			#clock-cells = < 0x0 >;          /* in zephyr/dts/arm/microchip/sam/sama7d6.dtsi:32 */
			clock-frequency = < 0x16e3600 >; /* in zephyr/boards/microchip/sam/sama7d65_curiosity/sama7d65_curiosity.dts:26 */
			phandle = < 0x2 >;               /* in zephyr/dts/arm/microchip/sam/sama7d6.dtsi:56 */
		};

		/* node '/clocks/slow_xtal' defined in zephyr/dts/arm/microchip/sam/sama7d6.dtsi:35 */
		slow_xtal: slow_xtal {
			compatible = "fixed-clock";   /* in zephyr/dts/arm/microchip/sam/sama7d6.dtsi:36 */
			#clock-cells = < 0x0 >;       /* in zephyr/dts/arm/microchip/sam/sama7d6.dtsi:37 */
			clock-frequency = < 0x8000 >; /* in zephyr/boards/microchip/sam/sama7d65_curiosity/sama7d65_curiosity.dts:30 */
			phandle = < 0x3 >;            /* in zephyr/dts/arm/microchip/sam/sama7d6.dtsi:63 */
		};
	};

	/* node '/ddram@60000000' defined in zephyr/boards/microchip/sam/sama7d65_curiosity/sama7d65_curiosity.dts:34 */
	ddram: ddram@60000000 {
		compatible = "ddram";            /* in zephyr/boards/microchip/sam/sama7d65_curiosity/sama7d65_curiosity.dts:35 */
		reg = < 0x60000000 0x40000000 >; /* in zephyr/boards/microchip/sam/sama7d65_curiosity/sama7d65_curiosity.dts:36 */
	};
};
